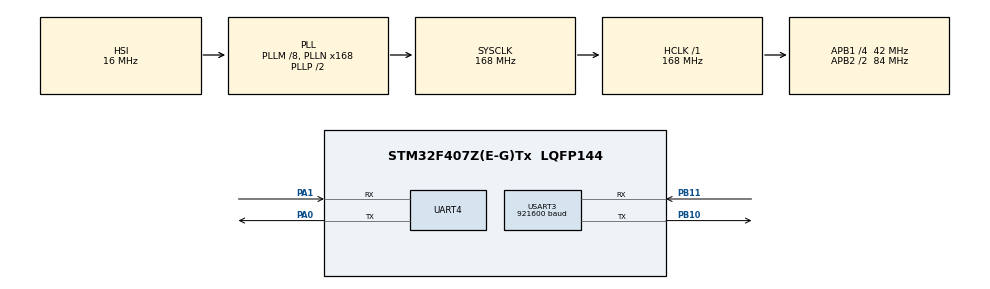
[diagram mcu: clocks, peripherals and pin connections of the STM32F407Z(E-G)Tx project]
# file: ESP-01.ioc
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Dma.Request0=UART4_RX
Dma.UART4_RX.0.Direction=DMA_PERIPH_TO_MEMORY
Dma.UART4_RX.0.FIFOMode=DMA_FIFOMODE_DISABLE
Dma.UART4_RX.0.Instance=DMA1_Stream2
Dma.UART4_RX.0.MemDataAlignment=DMA_MDATAALIGN_BYTE
Dma.UART4_RX.0.MemInc=DMA_MINC_ENABLE
Dma.UART4_RX.0.Mode=DMA_CIRCULAR
Dma.UART4_RX.0.PeriphDataAlignment=DMA_PDATAALIGN_BYTE
Dma.UART4_RX.0.PeriphInc=DMA_PINC_DISABLE
Dma.UART4_RX.0.Priority=DMA_PRIORITY_LOW
Mcu.Family=STM32F4
Mcu.Name=STM32F407Z(E-G)Tx
Mcu.Package=LQFP144
NVIC.PriorityGroup=NVIC_PRIORITYGROUP_4
NVIC.TIM6_DAC_IRQn=true\:1\:0\:true\:false\:true\:true\:true\:true
NVIC.UART4_IRQn=true\:0\:0\:false\:false\:true\:true\:true\:true
PA0-WKUP.Mode=Asynchronous
PA0-WKUP.Signal=UART4_TX
PA1.Mode=Asynchronous
PA1.Signal=UART4_RX
PA13.Mode=Serial_Wire
PA13.Signal=SYS_JTMS-SWDIO
PA14.Mode=Serial_Wire
PA14.Signal=SYS_JTCK-SWCLK
PB10.Mode=Asynchronous
PB10.Signal=USART3_TX
PB11.Mode=Asynchronous
PB11.Signal=USART3_RX
PC14-OSC32_IN.Mode=LSE-External-Oscillator
PC14-OSC32_IN.Signal=RCC_OSC32_IN
PC15-OSC32_OUT.Mode=LSE-External-Oscillator
PC15-OSC32_OUT.Signal=RCC_OSC32_OUT
PH0-OSC_IN.Mode=HSE-External-Oscillator
PH0-OSC_IN.Signal=RCC_OSC_IN
PH1-OSC_OUT.Mode=HSE-External-Oscillator
PH1-OSC_OUT.Signal=RCC_OSC_OUT
ProjectManager.HeapSize=0x200
ProjectManager.StackSize=0x800
ProjectManager.TargetToolchain=STM32CubeIDE
RCC.48MHZClocksFreq_Value=84000000
RCC.AHBFreq_Value=168000000
RCC.APB1CLKDivider=RCC_HCLK_DIV4
RCC.APB1Freq_Value=42000000
RCC.APB1TimFreq_Value=84000000
RCC.APB2CLKDivider=RCC_HCLK_DIV2
RCC.APB2Freq_Value=84000000
RCC.APB2TimFreq_Value=168000000
RCC.CortexFreq_Value=168000000
RCC.HCLKFreq_Value=168000000
RCC.HSE_VALUE=8000000
RCC.HSI_VALUE=16000000
RCC.PLLM=8
RCC.PLLN=168
RCC.SYSCLKFreq_VALUE=168000000
RCC.SYSCLKSource=RCC_SYSCLKSOURCE_PLLCLK
RCC.VCOOutputFreq_Value=336000000
UART4.VirtualMode=Asynchronous
USART3.BaudRate=921600
USART3.VirtualMode=VM_ASYNC
VP_TIM6_VS_ClockSourceINT.Mode=Enable_Timer
VP_TIM6_VS_OPM.Mode=OPM_bit
board=custom

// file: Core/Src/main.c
/* USER CODE BEGIN Header */
/**
  ******************************************************************************
  * @file           : main.c
  * @brief          : Main program body
  ******************************************************************************
  * @attention
  *
  * Copyright (c) 2022 STMicroelectronics.
  * All rights reserved.
  *
  * This software is licensed under terms that can be found in the LICENSE file
  * in the root directory of this software component.
  * If no LICENSE file comes with this software, it is provided AS-IS.
  *
  ******************************************************************************
  */
/* USER CODE END Header */
#include "main.h"
#include "dma.h"
#include "tim.h"
#include "usart.h"
#include "gpio.h"

/* USER CODE BEGIN Includes */
#include "ESP8266.h"
#include "stdio.h"
/* USER CODE END Includes */

void SystemClock_Config(void);

int main(void)
{

  /* MCU Configuration--------------------------------------------------------*/

  /* Reset of all peripherals, Initializes the Flash interface and the Systick. */
  HAL_Init();

  /* Configure the system clock */
  SystemClock_Config();

  /* Initialize all configured peripherals */
  MX_GPIO_Init();
  MX_DMA_Init();
  MX_UART4_Init();
  MX_TIM6_Init();
  MX_USART3_UART_Init();
  /* USER CODE BEGIN 2 */

  char buf[128];

  init();

  sendCmd("ATE0"    , "OK" , 1000);  			//关闭回显
  sendCmd("AT+CWMODE_DEF=3","OK",1500);			//设置ESP8266为AP/STA模式

  //设置模块的AP模式
  sprintf(buf,"AT+CWSAP=\"%s\",\"%s\",%s,%s","ATK_ESP8266","12345678","10","4");
  sendCmd(buf,"OK",2000);

  /* 设置模块AP当前IP地址 */
  sprintf(buf,"AT+CIPAP_CUR=\"%s\",\"%s\",\"%s\"", "192.168.0.233","192.168.5.1","255.255.255.0");
  sendCmd(buf, "OK", 1500);

  //创建多连接
  sendCmd("AT+CIPMUX=1","OK",1000);

  //创建模块TCP服务器
  //创建TCP服务器之后，会自动启动TCP服务监听，当有TCP客户端连接时，会有CONNECT提示
  sprintf(buf,"AT+CIPSERVER=%s,%s","1","1001");
  sendCmd(buf,"OK",2000);

  /* USER CODE END 2 */

  /* Infinite loop */
  while (1)
  {

  }
}

void SystemClock_Config(void)
{
  RCC_OscInitTypeDef RCC_OscInitStruct = {0};
  RCC_ClkInitTypeDef RCC_ClkInitStruct = {0};

  /** Configure the main internal regulator output voltage
  */
  __HAL_RCC_PWR_CLK_ENABLE();
  __HAL_PWR_VOLTAGESCALING_CONFIG(PWR_REGULATOR_VOLTAGE_SCALE1);

  /** Initializes the RCC Oscillators according to the specified parameters
  * in the RCC_OscInitTypeDef structure.
  */
  RCC_OscInitStruct.OscillatorType = RCC_OSCILLATORTYPE_HSI;
  RCC_OscInitStruct.HSIState = RCC_HSI_ON;
  RCC_OscInitStruct.HSICalibrationValue = RCC_HSICALIBRATION_DEFAULT;
  RCC_OscInitStruct.PLL.PLLState = RCC_PLL_ON;
  RCC_OscInitStruct.PLL.PLLSource = RCC_PLLSOURCE_HSI;
  RCC_OscInitStruct.PLL.PLLM = 8;
  RCC_OscInitStruct.PLL.PLLN = 168;
  RCC_OscInitStruct.PLL.PLLP = RCC_PLLP_DIV2;
  RCC_OscInitStruct.PLL.PLLQ = 4;
  if (HAL_RCC_OscConfig(&RCC_OscInitStruct) != HAL_OK)
  {
    Error_Handler();
  }

  /** Initializes the CPU, AHB and APB buses clocks
  */
  RCC_ClkInitStruct.ClockType = RCC_CLOCKTYPE_HCLK|RCC_CLOCKTYPE_SYSCLK
                              |RCC_CLOCKTYPE_PCLK1|RCC_CLOCKTYPE_PCLK2;
  RCC_ClkInitStruct.SYSCLKSource = RCC_SYSCLKSOURCE_PLLCLK;
  RCC_ClkInitStruct.AHBCLKDivider = RCC_SYSCLK_DIV1;
  RCC_ClkInitStruct.APB1CLKDivider = RCC_HCLK_DIV4;
  RCC_ClkInitStruct.APB2CLKDivider = RCC_HCLK_DIV2;

  if (HAL_RCC_ClockConfig(&RCC_ClkInitStruct, FLASH_LATENCY_5) != HAL_OK)
  {
    Error_Handler();
  }
}

void Error_Handler(void)
{
  __disable_irq();
  while (1)
  {
  }
}
